# USB_USB_OTGSSC2_53900000h register map
Vendor: Texas Instruments
Peripheral module from a debugger description file (folder AM261x).
Registers are 32-bit, access not given, reset values left out (the file's numbers can be read two ways) unless marked. A register's access mark holds for its fields unless they carry their own. Offsets are as the file gives them; lines under a group give offsets from that group; [hi:lo] are bit positions; {n}, {i} and the like mark numbered series; 'fields as' and 'values as' point back to an identical list; <NAME> marks a mode.

## USB_OTGSSC2
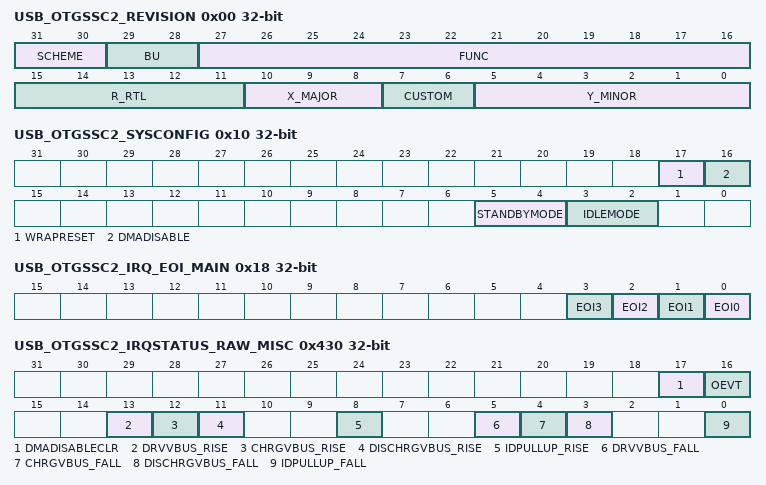
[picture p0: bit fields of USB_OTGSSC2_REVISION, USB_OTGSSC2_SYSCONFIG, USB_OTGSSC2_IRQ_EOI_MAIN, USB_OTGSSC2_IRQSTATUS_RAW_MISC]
0x00 USB_OTGSSC2_REVISION ro — IP Revision Identifier (X.Y.R)Used by software to track features, bugs, and compatibility.
  [31:30] SCHEME — Old vs. current REVISION encoding scheme.Read 0x0 = LEGACY, Legacy ASP or WBU scheme Read 0x1 = H08, Highlander 0.8 scheme
  [29:28] BU — Business UnitRead 0x0 = DSPSRead 0x1 = WBU
  [27:16] FUNC — Function indicates a software compatible module family. If there is no level of software compatibility a new Func number [and hence REVISION] should be assigned.
  [15:11] R_RTL — RTL Version [R], maintained by IP design owner.
  [10:8] X_MAJOR — Major Revision [X], maintained by IP specification owner.Read 0x1 V10, USBOTGSSMMAV10GS80 Read 0x2 V20, USBOTGSSMMAV20GS80
  [7:6] CUSTOM — Indicates a special version for a particular device.Consequence of use may avoid use of standard Chip Support Library [CSL] / Drivers.Read 0x0 STANDARD, Non custom [standard] revision
  [5:0] Y_MINOR — Minor Revision [Y], maintained by IP specification owner..
0x10 USB_OTGSSC2_SYSCONFIG rw — Controls various parameters of the master and slave interfaces.
  [17] WRAPRESET — Software reset for the wrapper-MMR set. Self-clearing.Does not effect the core-MMR set.Read 0 = DONE, Wrapper reset is done / inactive Write 0 = NOOP, No action Write 1 = DORST, Request wrapper reset Read 1 = ACTIVE, Wrapper reset is ongoing
  [16] DMADISABLE — Disable/Enable control of the DMA master [initiator] to block read/write accesses. Bit is auto-cleared [to 0] by HW in case of outgoing access, but must be set [to 1] manually.Write 0 = ENABLE, Enable the DMA. The enabling can also be done by the hardware, i.e. bit it auto-cleared. Read 0 = ENABLED, DMA is enabled, outgoing read/write accesses are possible. When in smart-standby mode, standby exit is requested. Read 1 = DISABLED, DMA is disabled, outgoing read/write accesses are blocked. When in smart-standby mode, standby is requested. Write 1 = DISABLE, Disable the DMA. SW must ensure that there are no ongoing transactions before setting this bit.The disabling can only be done by software.
  [5:4] STANDBYMODE — PM mode of local initiator [master]. Initiator may generate read/write transaction as long as it is out of STANDBY state.0x0 = FORCE, Force-standby: initiator is unconditionally placed in standby state. 0x1 = NO, No-standby: initiator is unconditionally placed out of standby state. 0x2 = SMART, Smart-standby: initiator's standby state depends on internal conditions, i.e. the module's functional requirements.Asynchronous wakeup events cannot be generated. 0x3 = SMART_WAKEUP, Smart-Standby, wakeup-capable: initiator's standby state depends on internal conditions, i.e. the module's functional requirements.Asynchronous wakeup events can be generated.
  [3:2] IDLEMODE — PM mode of local target [target]. Target shall be capable of handling read/write transaction as long as it is out of IDLE state.0x0 = FORCE, Force-idle mode: local target's idle state follows [acknowledges] the system's idle requests unconditionally, regardless of the IP module's internal requirements. 0x1 = NO, No-idle mode: local target never enters idle state. 0x2 = SMART, Smart-idle mode: local target's idle state eventually follows [acknowledges] the system's idle requests, depending on the IP module's internal requirements.Module shall not generate [IRQ- or DMA-request-related] wakeup events. 0x3 = SMART_WAKEUP, Smart-idle wakeup-capable mode: local target's idle state eventually follows [acknowledges] the system's idle requests, depending on the IP module's internal requirements.IP module may generate [IRQ- or DMA-request-related] wakeup events when in idle state.
0x18 USB_OTGSSC2_IRQ_EOI_MAIN rw — Software End-Of-Interrupt, MAIN lines: Flag the end current event to allow the generation of further pulses on the line.Write 1 to a bit to EOI the corresponding line.Unused when using the level interrupt line (depending on module integration).
  [n] EOI{n} (n=0..3) — Write 1 to flag End Of Interrupt 'main' #{n}Write 0 = NOOP, No action Read 0 = READ0, Read returns zero Write 1 = EOI, Flag EOI
{0x20+0x10*i} USB_OTGSSC2_IRQSTATUS_RAW_MAIN_{i} (i=0..3) — Raw status of host/device interrupt line. Is set even if event is not enabled.Write 1 to set, used mostly for debug (regular status also gets set if enabled).
  [0] COREIRQ_ST — IRQ status for core: see status register IMAN.IPRead 0 = NONE, No event pending Write 0 = NOACTION, No action Write 1 = SET, Trigger IRQ event by software Read 1 = PENDING, IRQ event pending Note: W1toSet: IRQSTATUS_MAIN.COREIRQ_ST (access R/W1TS)
{0x24+0x10*i} USB_OTGSSC2_IRQSTATUS_MAIN_{i} (i=0..3) — 'regular' status of main core interrupt request. Set only when enabled, self-cleared unless it was set by writing to STATUS_RAW, for debug.Write 1 to clear (raw status also gets cleared).
  [0] COREIRQ_ST — IRQ status for core: see status register IMAN.IPRead 0 = NONE, No event pending Write 0 = NOACTION, No action Write 1 = CLEAR, Clear pending event, if any Read 1 = PENDING, IRQ event pending Note: W1toClr: IRQSTATUS_RAW_MAIN.COREIRQ_ST (access R/W0TC)
{0x28+0x10*i} USB_OTGSSC2_IRQENABLE_SET_MAIN_{i} (i=0..3) — Enable of main core interrupt request. Write 1 to set (i.e. to enable interrupt).Readout is the same as corresponding _CLR register.
  [0] COREIRQ_EN — IRQ enable for main core interruptRead 0 = DISABLED, IRQ event is disabled Write 0 = NOACTION, No action Write 1 = SET, Set IRQ enable [i.e. enable event] Read 1 = ENABLED, IRQ event is enabled Note: W1toSet: IRQENABLE_CLR_MAIN.COREIRQ_EN (access R/W1TS)
{0x2C+0x10*i} USB_OTGSSC2_IRQENABLE_CLR_MAIN_{i} (i=0..3) — Enable of main core interrupt request. Write 1 to clear (i.e. to disable interrupt). Readout is the same as corresponding _SET register.
  [0] COREIRQ_EN — IRQ enable for main core interruptRead 0 = DISABLED, IRQ event is disabled Write 0 = NOACTION, No action Write 1 = CLEAR, Clear IRQ enable [i.e. disable event] Read 1 = ENABLED, IRQ event is enabled Note: W1toClr: IRQENABLE_SET_MAIN.COREIRQ_EN (access R/W0TC)
0x42C USB_OTGSSC2_IRQ_EOI_MISC rw — Software End-Of-Interrupt, MISC line: Flag the end current event to allow the generation of further pulses on the line.Write 1 to a bit to EOI the corresponding line.Unused when using the level interrupt line (depending on module integration).
  [0] EOI_MISC — Write 1 to flag End Of Interrupt 'MISC'Write 0 = NOOP, No action Read 0 = READ0, Read returns zero Write 1 = EOI, Flag EOI
0x430 USB_OTGSSC2_IRQSTATUS_RAW_MISC — Raw status of 'misc' low-priority interrupt requests. Set even if event is not enabled.Write 1 to set the (raw) status, mostly for debug (regular status also gets set).
  [17] DMADISABLECLR — DMA-disable self-clear IRQ status: SYSCONFIG.dmadisable HW-cleared [to 0] because of DMA access. Not triggered by a SW clear.Read 0 = NONE, No event pending Write 0 = NOACTION, No action Write 1 = SET, Trigger IRQ event by software Read 1 = PENDING, IRQ event pending (access R/W1TS)
  [16] OEVT — OTG event in core, IRQ status: see status register OEVTRead 0 = NONE, No event pending Write 0 = NOACTION, No action Write 1 = SET, Trigger IRQ event by software Read 1 = PENDING, IRQ event pending Note: W1toSet: IRQSTATUS_MISC.oevt (access R/W1TS)
  [13] DRVVBUS_RISE — Drive VBUS control rise IRQ statusRead 0 = NONE, No event pending Write 0 = NOACTION, No action Write 1 = SET, Trigger IRQ event by software Read 1 = PENDING, IRQ event pending Note: W1toSet: IRQSTATUS_MISC.drvvbus_rise (access R/W1TS)
  [12] CHRGVBUS_RISE — Charge VBUS control rise IRQ statusRead 0 = NONE, No event pending Write 0 = NOACTION, No action Write 1 = SET, Trigger IRQ event by software Read 1 = PENDING, IRQ event pending Note: W1toSet: IRQSTATUS_MISC.chrgvbus_rise (access R/W1TS)
  [11] DISCHRGVBUS_RISE — Discharge VBUS control rise IRQ statusRead 0 = NONE, No event pending Write 0 = NOACTION, No action Write 1 = SET, Trigger IRQ event by software Read 1 = PENDING, IRQ event pending Note: W1toSet: IRQSTATUS_MISC.dischrgvbus_rise (access R/W1TS)
  [8] IDPULLUP_RISE — ID pullup control rise IRQ statusRead 0 = NONE, No event pending Write 0 = NOACTION, No action Write 1 = SET, Trigger IRQ event by software Read 1 = PENDING, IRQ event pending (access R/W1TS)
  [5] DRVVBUS_FALL — Drive VBUS control fall IRQ statusRead 0 = NONE, No event pending Write 0 = NOACTION, No action Write 1 = SET, Trigger IRQ event by software Read 1 = PENDING, IRQ event pending Note: W1toSet: IRQSTATUS_MISC.drvvbus_rise (access R/W1TS)
  [4] CHRGVBUS_FALL — Charge VBUS control fall IRQ statusRead 0 = NONE, No event pending Write 0 = NOACTION, No action Write 1 = SET, Trigger IRQ event by software Read 1 = PENDING, IRQ event pending Note: W1toSet: IRQSTATUS_MISC.chrgvbus_rise (access R/W1TS)
  [3] DISCHRGVBUS_FALL — Discharge VBUS control fall IRQ statusRead 0 = NONE, No event pending Write 0 = NOACTION, No action Write 1 = SET, Trigger IRQ event by software Read 1 = PENDING, IRQ event pending Note: W1toSet: IRQSTATUS_MISC.dischrgvbus_rise (access R/W1TS)
  [0] IDPULLUP_FALL — ID pullup control fall IRQ statusRead 0 = NONE, No event pending Write 0 = NOACTION, No action Write 1 = SET, Trigger IRQ event by software Read 1 = PENDING, IRQ event pending Note: W1toSet: IRQSTATUS_MISC.idpullup_rise (access R/W1TS)
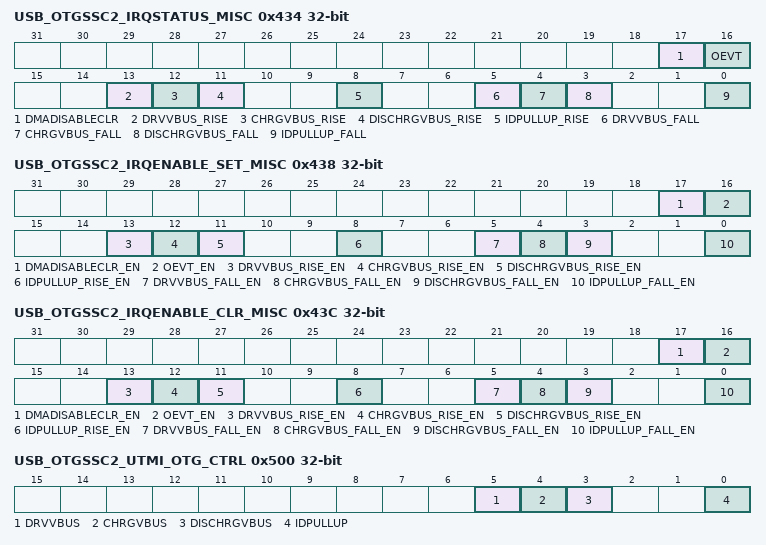
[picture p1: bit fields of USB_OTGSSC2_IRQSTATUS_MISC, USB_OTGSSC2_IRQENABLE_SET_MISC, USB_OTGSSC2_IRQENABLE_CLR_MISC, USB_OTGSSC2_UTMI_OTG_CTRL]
0x434 USB_OTGSSC2_IRQSTATUS_MISC — 'regular' status of 'misc' low-priority interrupt requests. Set only when enabled.Write 1 to clear after interrupt has been serviced (raw status also gets cleared).
  [17] DMADISABLECLR — DMA-disable self-clear IRQ status: SYSCONFIG.dmadisable HW-cleared [to 0] because of DMA access. Not triggered by a SW clear.Read 0 = NONE, No event pending Write 0 = NOACTION, No action Write 1 = SET, Trigger IRQ event by software Read 1 = PENDING, IRQ event pending Note: W1toClr: IRQSTATUS_RAW_MISC.dmadisableclr (access R/W0TC)
  [16] OEVT — OTG event in core, IRQ status: see status register OEVTRead 0 = NONE, No event pending Write 0 = NOACTION, No action Write 1 = SET, Trigger IRQ event by software Read 1 = PENDING, IRQ event pending Note: W1toSet: IRQSTATUS_RAW_MISC.oevt (access R/W1TS)
  [13] DRVVBUS_RISE — Drive VBUS control rise IRQ statusRead 0 = NONE, No event pending Write 0 = NOACTION, No action Write 1 = SET, Trigger IRQ event by software Read 1 = PENDING, IRQ event pending Note: W1toSet: IRQSTATUS_RAW_MISC.drvvbus_rise (access R/W1TS)
  [12] CHRGVBUS_RISE — Charge VBUS control rise IRQ statusRead 0 = NONE, No event pending Write 0 = NOACTION, No action Write 1 = SET, Trigger IRQ event by software Read 1 = PENDING, IRQ event pending Note: W1toSet: IRQSTATUS_RAW_MISC.chrgvbus_rise (access R/W1TS)
  [11] DISCHRGVBUS_RISE — Discharge VBUS control rise IRQ statusRead 0 = NONE, No event pending Write 0 = NOACTION, No action Write 1 = SET, Trigger IRQ event by software Read 1 = PENDING, IRQ event pending Note: W1toSet: IRQSTATUS_RAW_MISC.dischrgvbus_rise (access R/W1TS)
  [8] IDPULLUP_RISE — ID pullup control rise IRQ statusRead 0 = NONE, No event pending Write 0 = NOACTION, No action Write 1 = SET, Trigger IRQ event by software Read 1 = PENDING, IRQ event pending Note: W1toClr: IRQSTATUS_RAW_MISC.idpullup_rise (access R/W0TC)
  [5] DRVVBUS_FALL — Drive VBUS control fall IRQ statusRead 0 = NONE, No event pending Write 0 = NOACTION, No action Write 1 = SET, Trigger IRQ event by software Read 1 = PENDING, IRQ event pending Note: W1toSet: IRQSTATUS_RAW_MISC.drvvbus_fall (access R/W1TS)
  [4] CHRGVBUS_FALL — Charge VBUS control fall IRQ statusRead 0 = NONE, No event pending Write 0 = NOACTION, No action Write 1 = SET, Trigger IRQ event by software Read 1 = PENDING, IRQ event pending Note: W1toSet: IRQSTATUS_RAW_MISC.chrgvbus_fall (access R/W1TS)
  [3] DISCHRGVBUS_FALL — Discharge VBUS control fall IRQ statusRead 0 = NONE, No event pending Write 0 = NOACTION, No action Write 1 = SET, Trigger IRQ event by software Read 1 = PENDING, IRQ event pending Note: W1toSet: IRQSTATUS_RAW_MISC.dischrgvbus_fall (access R/W1TS)
  [0] IDPULLUP_FALL — ID pullup control fall IRQ statusRead 0 = NONE, No event pending Write 0 = NOACTION, No action Write 1 = SET, Trigger IRQ event by software Read 1 = PENDING, IRQ event pending Note: W1toSet: IRQSTATUS_RAW_MISC.idpullup_fall (access R/W1TS)
0x438 USB_OTGSSC2_IRQENABLE_SET_MISC — Enable of 'misc' low-priority interrupt requests. Write 1 to set (i.e. to disable interrupt).Readout is the same as corresponding _CLR register.
  [17] DMADISABLECLR_EN — DMA-disable self-clear, IRQ enableRead 0 DISABLEDIRQ event is disabled Write 0 NOACTIONNo action Write 1 SETSet IRQ enable [i.e. enable event] Read 1 ENABLEDIRQ event is enabled (access R/W1TS)
  [16] OEVT_EN — OTG event in core, IRQ status: see status register OEVTRead 0 DISABLEDIRQ event is disabled Write 0 NOACTIONNo action Write 1 SETSet IRQ enable [i.e. enable event] Read 1 ENABLEDIRQ event is enabled (access R/W1TS)
  [13] DRVVBUS_RISE_EN — Drive VBUS control rise IRQ statusRead 0 DISABLEDIRQ event is disabled Write 0 NOACTIONNo action Write 1 SETSet IRQ enable [i.e. enable event] Read 1 ENABLEDIRQ event is enabled (access R/W1TS)
  [12] CHRGVBUS_RISE_EN — Charge VBUS control rise IRQ statusRead 0 DISABLEDIRQ event is disabled Write 0 NOACTIONNo action Write 1 SETSet IRQ enable [i.e. enable event] Read 1 ENABLEDIRQ event is enabled (access R/W1TS)
  [11] DISCHRGVBUS_RISE_EN — Discharge VBUS control rise IRQ statusRead 0 DISABLEDIRQ event is disabled Write 0 NOACTIONNo action Write 1 SETSet IRQ enable [i.e. enable event] Read 1 ENABLEDIRQ event is enabled (access R/W1TS)
  [8] IDPULLUP_RISE_EN — ID pullup control rise IRQ statusRead 0 DISABLEDIRQ event is disabled Write 0 NOACTIONNo action Write 1 SETSet IRQ enable [i.e. enable event] Read 1 ENABLEDIRQ event is enabled (access R/W1TS)
  [5] DRVVBUS_FALL_EN — Drive VBUS control fall IRQ statusRead 0 DISABLEDIRQ event is disabled Write 0 NOACTIONNo action Write 1 SETSet IRQ enable [i.e. enable event] Read 1 ENABLEDIRQ event is enabled (access R/W1TS)
  [4] CHRGVBUS_FALL_EN — Charge VBUS control fall IRQ statusRead 0 DISABLEDIRQ event is disabled Write 0 NOACTIONNo action Write 1 SETSet IRQ enable [i.e. enable event] Read 1 ENABLEDIRQ event is enabled (access R/W1TS)
  [3] DISCHRGVBUS_FALL_EN — Discharge VBUS control fall IRQ statusRead 0 DISABLEDIRQ event is disabled Write 0 NOACTIONNo action Write 1 SETSet IRQ enable [i.e. enable event] Read 1 ENABLEDIRQ event is enabled (access R/W1TS)
  [0] IDPULLUP_FALL_EN — ID pullup control fall IRQ statusRead 0 DISABLEDIRQ event is disabled Write 0 NOACTIONNo action Write 1 SETSet IRQ enable [i.e. enable event] Read 1 ENABLEDIRQ event is enabled (access R/W1TS)
0x43C USB_OTGSSC2_IRQENABLE_CLR_MISC — Enable of 'misc' low-priority interrupt requests. Write 1 to clear (i.e. to disable interrupt).Readout is the same as corresponding _SET register.
  [17] DMADISABLECLR_EN — DMA-disable self-clear, IRQ enableRead 0 DISABLEDIRQ event is disabled Write 0 NOACTIONNo action Write 1 CLEARClear IRQ enable [i.e. disable event] Read 1 ENABLEDIRQ event is enabled (access R/W0TC)
  [16] OEVT_EN — OTG event in core, IRQ status: see status register OEVTRead 0 DISABLEDIRQ event is disabled Write 0 NOACTIONNo action Write 1 CLEARClear IRQ enable [i.e. disable event] Read 1 ENABLEDIRQ event is enabled (access R/W0TC)
  [13] DRVVBUS_RISE_EN — Drive VBUS control rise IRQ statusRead 0 DISABLEDIRQ event is disabled Write 0 NOACTIONNo action Write 1 CLEARClear IRQ enable [i.e. disable event] Read 1 ENABLEDIRQ event is enabled (access R/W0TC)
  [12] CHRGVBUS_RISE_EN — Charge VBUS control rise IRQ statusRead 0 DISABLEDIRQ event is disabled Write 0 NOACTIONNo action Write 1 CLEARClear IRQ enable [i.e. disable event] Read 1 ENABLEDIRQ event is enabled Note: W1toSet: IRQSTATUS_RAW_MISC.chrgvbus_rise (access R/W0TC)
  [11] DISCHRGVBUS_RISE_EN — Discharge VBUS control rise IRQ statusRead 0 DISABLEDIRQ event is disabled Write 0 NOACTIONNo action Write 1 CLEARClear IRQ enable [i.e. disable event] Read 1 ENABLEDIRQ event is enabled (access R/W0TC)
  [8] IDPULLUP_RISE_EN — ID pullup control rise IRQ statusRead 0 DISABLEDIRQ event is disabled Write 0 NOACTIONNo action Write 1 CLEARClear IRQ enable [i.e. disable event] Read 1 ENABLEDIRQ event is enabled (access R/W0TC)
  [5] DRVVBUS_FALL_EN — Drive VBUS control fall IRQ statusRead 0 DISABLEDIRQ event is disabled Write 0 NOACTIONNo action Write 1 CLEARClear IRQ enable [i.e. disable event] Read 1 ENABLEDIRQ event is enabled (access R/W0TC)
  [4] CHRGVBUS_FALL_EN — Charge VBUS control fall IRQ statusRead 0 DISABLEDIRQ event is disabled Write 0 NOACTIONNo action Write 1 CLEARClear IRQ enable [i.e. disable event] Read 1 ENABLEDIRQ event is enabled (access R/W0TC)
  [3] DISCHRGVBUS_FALL_EN — Discharge VBUS control fall IRQ statusRead 0 DISABLEDIRQ event is disabled Write 0 NOACTIONNo action Write 1 CLEARClear IRQ enable [i.e. disable event] Read 1 ENABLEDIRQ event is enabled (access R/W0TC)
  [0] IDPULLUP_FALL_EN — ID pullup control fall IRQ statusRead 0 DISABLEDIRQ event is disabled Write 0 NOACTIONNo action Write 1 CLEARClear IRQ enable [i.e. disable event] Read 1 ENABLEDIRQ event is enabled (access R/W0TC)
0x500 USB_OTGSSC2_UTMI_OTG_CTRL ro — This register describes the utmi otg control, which is used to coordinate between usbotgss_core and USB_OTG.
  [5] DRVVBUS — Drive 5V on VBUS. Plays the role of 'hub_vbus_ctrl' in non-OTG host mode.Read 0 = NOACTION, no action Read 1 = DRIVE, drive VBUS
  [4] CHRGVBUS — Charge VBUS through a resistor for VBUS-pulsing SRP.Read 0 = NOACTION, no action Read 1 = CHARGE, charge VBUS
  [3] DISCHRGVBUS — Discharge VBUS through a resistor, until the session-end VBUS state is reached.Read 0 = NOACTION, no action Read 1 = DISCHARGE, discharge VBUS
  [0] IDPULLUP — Pull-up to the [OTG] ID line to allow its sampling.Read 0 = DISABLE, Disable sampling of ID line. Read 1 = ENABLE, Enable sampling of ID line.
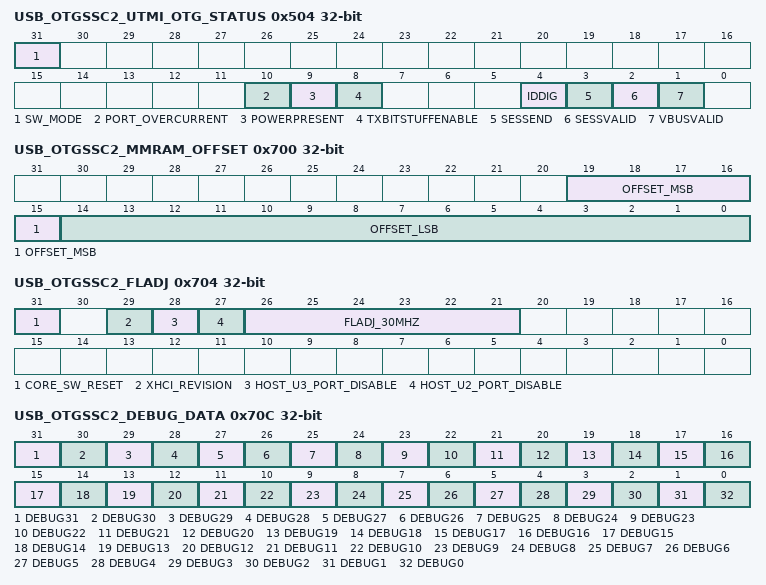
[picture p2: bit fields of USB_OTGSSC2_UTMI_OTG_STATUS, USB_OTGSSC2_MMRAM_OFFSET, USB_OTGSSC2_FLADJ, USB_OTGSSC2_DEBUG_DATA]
0x504 USB_OTGSSC2_UTMI_OTG_STATUS rw — This register describes the utmi otg status, which is used to coordinate between usbotgss_core and USB_OTG.
  [31] SW_MODE — Controls the source of UTMI / PIPE status for VBUS and OTG ID [vbusvalid, sessvalid, sessend, iddig, powerpresent]0 = IO, HW mode: OTG ID and VBUS status for the USB controller are taken from the UTMI inputs signals 1 = SW, SW mode: OTG ID and VBUS status for the USB controller are taken from the fields of the current register.
  [10] PORT_OVERCURRENT — Over-current status, for non-OTG host only.0 = NONE, No over-current indication 1 = OC, Over-current indication
  [9] POWERPRESENT — SW-programmed value of PIPE3.0 PowerPresent [VBUS status] seen by the core, alternative to HW input.
  [8] TXBITSTUFFENABLE — SW-programmed UTMI output txbitstuffenable[h] Note: as per UTMI+, used only in UTMI Opmode 0b11 [i.e. SYNC and EOP generation disabled]0 = NOBS, No bitstuffing 1 = BS, Data bitstuffing enabled
  [4] IDDIG — SW-programmed value of UTMI+ IdDig [OTG ID status] seen by the core, alternative to HW input. Don't care until IdPullup = 1 for at least 50 ms0 = IDA, ID pin is grounded = OTG A = default Host 1 = IDB, ID pin is floating = OTG B = default Peripheral
  [3] SESSEND — SW-programmed value of UTMI+ SessEnd [VBUS status] seen by the core, alternative to HW input.0 = NOTENDED, VBUS is above Session-End threshold 1 =ENDED, VBUS is below Session-End threshold
  [2] SESSVALID — SW-programmed value of UTMI+ SessValid [VBUS status] seen by the core, alternative to HW inputs AValid and BValid.0 = NOTVALID, VBUS is below Session-Valid threshold 1 = VALID, VBUS is above Session-Valid threshold
  [1] VBUSVALID — SW-programmed value of UTMI+ VbusValid [VBUS status] seen by the core, alternative to HW input.0 = NOTVALID, VBUS is below Vbus-Valid threshold. 1 = VALID, VBUS is above Vbus-Valid threshold
0x508 USB_OTGSSC2_TXFIFO_DEPTH ro — Actual depth of Tx FIFO RAM (RAM1), in 64-bit words.Maximum value is GHWPARAMS7.DWC_USB3_RAM1_DEPTH.
  [15:0] TXFIFO_DEPTH
0x50C USB_OTGSSC2_RXFIFO_DEPTH ro — Actual depth of Rx FIFO RAM (RAM2), in 64-bit words.Maximum value is GHWPARAMS7.DWC_USB3_RAM2_DEPTH.
  [15:0] RXFIFO_DEPTH
0x700 USB_OTGSSC2_MMRAM_OFFSET access per field — Offset of Memory-mapped RAM accesses.Page is remapped from 0x8000 to 0xFFFF (32 kbyte).
  [19:15] OFFSET_MSB rw — Byte offset MSBits = page offset0x00 = CORE_BOT, Page offset for core MMR set, lower half.DO NOT USE: use static access at offset 0x10_000+ instead. 0x01 = CORE_TOP, Page offset for core MMR set, upper half.DO NOT USE: use static access at offset 0x10_000+ instead. 0x08 = RAM0_BASE, Base page offset for RAM0 [= core byte address 0x4_0000]: Rx FIFOs, descriptors, MMR.The RAM shall fit inside this page for up to 32 kByte = 8,192 x 64-bit words 0x10 = RAM1_BASE, Base page offset for RAM1 [= core byte address 0x8_0000]: Tx FIFOs.The RAM shall fit inside this page for up to 32 kByte = 8,192 x 64-bit words. 0x18 = RAM2_BASE, Base page offset for RAM2 [= core byte address 0xC_0000]: Rx FIFOs.The RAM shall fit inside this page for up to 32 kByte = 8,192 x 64-bit words.
  [14:0] OFFSET_LSB ro — Byte offset LSBits, always 0
0x704 USB_OTGSSC2_FLADJ rw — Jitter adjustment and other pseudo-static parameters.
  [31] CORE_SW_RESET — Active-high core software reset. Static, i.e. not self-clearing. After clearing, wait for reset completion by polling USBSTS.CNR bit.0 NORESETReset inactive 1 RESETReset active
  [29] XHCI_REVISION — Switches to the legacy xHCI 0.96 host SW API mode. Changes shall take place under core SW reset [bit 31].0 0_96xHCI version 0.96 1 1_0xHCI version 1.0 + errata
  [28] HOST_U3_PORT_DISABLE — USB3 port disable, overriding xHCI driver.0 ENPort can be enabled. 1 DISPort stops reporting connect/disconnect events and remains in disabled state.
  [27] HOST_U2_PORT_DISABLE — USB2 port disable, overriding xHCI driver.0 ENPort can be enabled. 1 DISPort stops reporting connect/disconnect events and remains in disabled state.
  [26:21] FLADJ_30MHZ — HS Jitter Adjustment, in 30 MHz periods
0x708 USB_OTGSSC2_DEBUG_CFG rw — Configuration of debug output (observability).
  [2:0] SEL — Selection of observed local signals0x0 = TIELODebug output is tied low [32'b0] 0x1 = UTMIDebug output is a selection of UTMI [USB2 PHY] interface signals 0x2 = PIPEDebug output is a selection of PIPE [USB3 PHY] interface signals 0x3 = COREDebug output is controller core's internal debug signals 0x4 = TRACE_LODebug output is lower 32 bits controller core's internal trace vector, selected by GDBGLSPMUX.TracePortMuxSel 0x5 = TRACE_HIDebug output is upper 32 bits controller core's internal trace vector, selected by GDBGLSPMUX.TracePortMuxSel
0x70C USB_OTGSSC2_DEBUG_DATA ro — data currently visible on DEBUG output (observability) portdepends on mode given in DEBUG_CFG.sel , shown only for sel = (1;2;3)all bits are tied low (0) when sel=0
  [31] DEBUG31 — Sel1:utmi_sessend ;sel2:pipe_rxstatus[2] ;sel3:core_sm2bl_cur_mode
  [30] DEBUG30 — Sel1:utmi_vbusvalid ;sel2:pipe_rxstatus[1] ;sel3:core_l1_suspend_com_n
  [29] DEBUG29 — Sel1:utmi_bvalid ;sel2:pipe_rxstatus[0] ;sel3:core_suspend_com_n
  [28] DEBUG28 — Sel1:utmi_avalid ;sel2:pipe_elecidle ;sel3:core_u2_dssr_state[3]
  [27] DEBUG27 — Sel1:utmi_iddig ;sel2:pipe_phystatus ;sel3:core_u2_dssr_state[2]
  [26] DEBUG26 — Sel1:utmi_hostdisconnect ;sel2:pipe_rxvalid ;sel3:core_u2_dssr_state[1]
  [25] DEBUG25 — Sel1:utmi_txbitstuffenableh ;sel2:pipe_rxdatak[3] ;sel3:core_u2_dssr_state[0]
  [24] DEBUG24 — Sel1:utmi_txbitstuffenable ;sel2:pipe_rxdatak[2] ;sel3:core_u2mac_txrx_state_1[4]
  [23] DEBUG23 — Sel1:utmi_dischrgvbus ;sel2:pipe_rxdatak[1] ;sel3:core_u2mac_txrx_state_1[3]
  [22] DEBUG22 — Sel1:utmi_chrgvbus ;sel2:pipe_rxdatak[0] ;sel3:core_u2mac_txrx_state_1[2]
  [21] DEBUG21 — Sel1:utmi_drvvbus ;sel2:pipe_rxpclk ;sel3:core_u2mac_txrx_state_1[1]
  [20] DEBUG20 — Sel1:utmi_dmpulldown ;sel2:pipe_rxtermination ;sel3:core_u2mac_txrx_state_1[0]
  [19] DEBUG19 — Sel1:utmi_dppulldown ;sel2:pipe_txswing ;sel3:core_u2mac_txrx_state_0[4]
  [18] DEBUG18 — Sel1:utmi_idpullup ;sel2:pipe_txmargin[2] ;sel3:core_u2mac_txrx_state_0[3]
  [17] DEBUG17 — Sel1:utmi_linestate[1] ;sel2:pipe_txmargin[1] ;sel3:core_u2mac_txrx_state_0[2]
  [16] DEBUG16 — Sel1:utmi_linestate[0] ;sel2:pipe_txmargin[0] ;sel3:core_u2mac_txrx_state_0[1]
  [15] DEBUG15 — Sel1:utmi_opmode[1] ;sel2:pipe_txdeemph[1] ;sel3:core_u2mac_txrx_state_0[0]
  [14] DEBUG14 — Sel1:utmi_opmode[0] ;sel2:pipe_txdeemph[0] ;sel3:core_u2_prt_state[4]
  [13] DEBUG13 — Sel1:utmi_termselect ;sel2:pipe_powerdown[1] ;sel3:core_u2_prt_state[3
  [12] DEBUG12 — Se1:utmi_xcvrselect[1] ;sel2:pipe_powerdown[0] ;sel3:core_u2_prt_state[2]
  [11] DEBUG11 — Sel1:utmi_xcvrselect[0] ;sel2:pipe_reset_n ;sel3:core_u2_prt_state[1]
  [10] DEBUG10 — Sel1:utmi_suspendm ;sel2:pipe_rxeqtraining ;sel3:core_u2_prt_state[0]
  [9] DEBUG9 — Sel1:utmi_reset ;sel2:pipe_rxpolarity ;sel3:core_gsts_buserraddvld
  [8] DEBUG8 — Sel1:utmi_rxerror ; sel2:pipe_txoneszeros ; sel3:debug_mclk_usof_number[0]
  [7] DEBUG7 — Sel1:utmi_rxvalidh sel2:pipe_txelecidle sel3:core_ltdb_link_state[3]
  [6] DEBUG6 — Sel1:utmi_rxvalid; sel2:pipe_txdetectrxloopback sel3:core_ltdb_link_state[2]
  [5] DEBUG5 — Sel1:utmi_rxactive; sel2:pipe_elasticitybuffermode; sel3:core_ltdb_link_state[1]
  [4] DEBUG4 — Sel1:utmi_txready; sel2:pipe_txdatak[3]; sel3:core_ltdb_link_state[0]
  [3] DEBUG3 — Sel1:utmi_txvalidh sel2:pipe_txdatak[2] sel3:core_ltdb_substate[3]
  [2] DEBUG2 — Sel1:utmi_txvalid sel2:pipe_txdatak[1] sel3:core_ltdb_substate[2]
  [1] DEBUG1 — Sel1:utmi_databus16_8 sel2:pipe_txdatak[0] sel3:core_ltdb_substate[1]
  [0] DEBUG0 — Sel1:utmi_clk sel2:pipe_txpclk sel3:core_ltdb_substate[0]
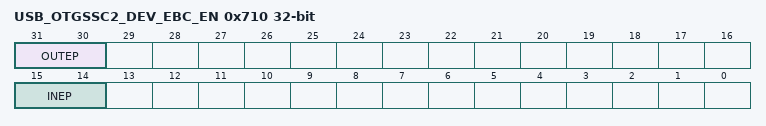
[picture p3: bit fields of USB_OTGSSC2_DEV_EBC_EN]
0x710 USB_OTGSSC2_DEV_EBC_EN rw — Enable External Buffer Control (EBC) for selected endpoints. Device mode only.
  [31:30] OUTEP — Enable EBC HW throttling for OUT EP, per bit [USB receive].To enable logical OUT EP #i, set DEV_EBC_EN[i+16] to 1.In DEPCFG command for this EP, DEPCMDPAR1[15] = LimitOutstandingTxDMA should then also be set to 1
  [15:14] INEP — Enable EBC HW throttling for IN EP [USB transmit].To enable logical EP IN #i, set DEV_EBC_EN[i] to 1.In DEPCFG command for this EP, DEPCMDPAR1[15] = LimitOutstandingTxDMA should then also be set to 1
